# M068 register map
File version: 0.1
Registers are 32-bit, read-write, reset 0x0 unless marked. A register's access mark holds for its fields unless they carry their own. Offsets are from the block's base; [hi:lo] are bit positions; {n}, {i} and the like mark numbered series.

## UDFS2 — UDC2(USB -Spec2.0 Device contoller)
Base 0x40008200
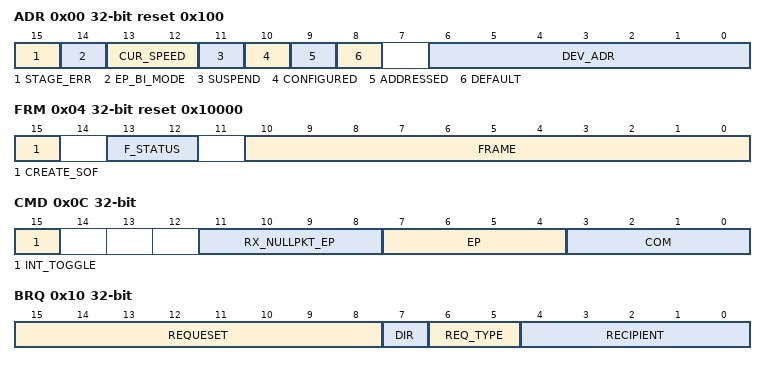
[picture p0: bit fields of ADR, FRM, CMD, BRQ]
0x00 ADR reset 0x100 — UDC2 Address State
  [15] STAGE_ERR, [14] EP_BI_MODE, [13:12] CUR_SPEED ro, [11] SUSPEND ro, [10] CONFIGURED, [9] ADDRESSED, [8] DEFAULT, [6:0] DEV_ADR
0x04 FRM reset 0x10000 — UDC2 Frame
  [15] CREATE_SOF, [13:12] F_STATUS ro, [10:0] FRAME ro
0x0C CMD — UDC2 Command
  [15] INT_TOGGLE, [11:8] RX_NULLPKT_EP ro, [7:4] EP, [3:0] COM
0x10 BRQ ro — UDC2 bRequest-bmRequest Type
  [15:8] REQUESET, [7] DIR, [6:5] REQ_TYPE, [4:0] RECIPIENT
0x14 WVL ro — UDC2 wValue
  [15:0] VALUE
0x18 WIDX ro — UDC2 wIndex
  [15:0] INDEX
0x1C WLGTH ro — UDC2 wLength
  [15:0] LENGTH
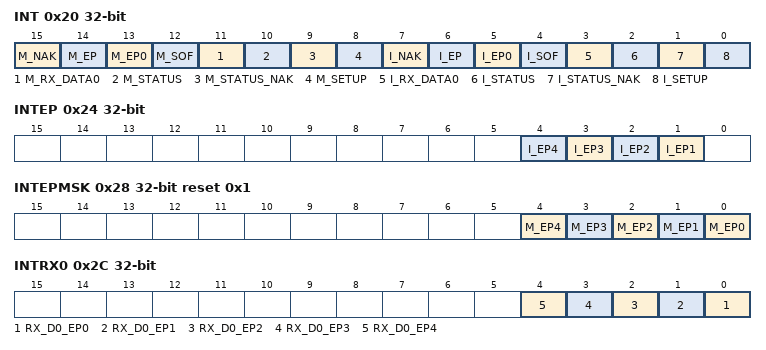
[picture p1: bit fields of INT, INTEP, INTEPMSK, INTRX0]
0x20 INT — UDC2 INT
  [15] M_NAK, [14] M_EP, [13] M_EP0, [12] M_SOF, [11] M_RX_DATA0, [10] M_STATUS, [9] M_STATUS_NAK, [8] M_SETUP, [7] I_NAK, [6] I_EP, [5] I_EP0, [4] I_SOF, [3] I_RX_DATA0, [2] I_STATUS, [1] I_STATUS_NAK, [0] I_SETUP
0x24 INTEP — UDC2 INT_EP
  [n] I_EP{n} (n=1..4)
0x28 INTEPMSK reset 0x1 — UDC2 INT_EP_MASK
  [n] M_EP{n} (n=0..4)
0x2C INTRX0 — UDC2 INT RX DATA0
  [n] RX_D0_EP{n} (n=0..4)
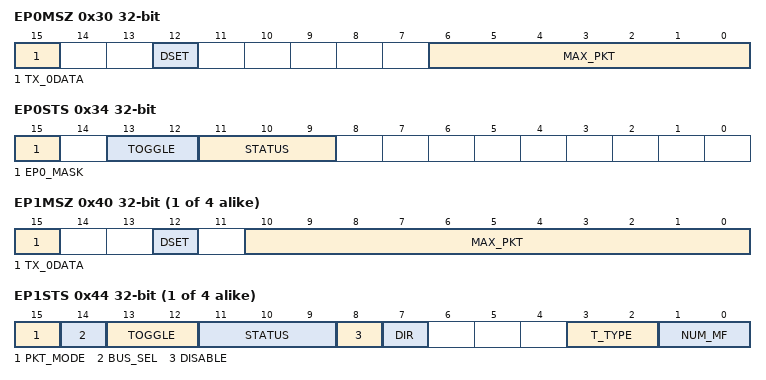
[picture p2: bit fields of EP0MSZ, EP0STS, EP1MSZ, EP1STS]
0x30 EP0MSZ — UDC2 EP0 Max Packet Size
  [15] TX_0DATA ro, [12] DSET ro, [6:0] MAX_PKT
0x34 EP0STS ro — UDC2 EP0 Status
  [15] EP0_MASK, [13:12] TOGGLE, [11:9] STATUS
0x38 EP0DSZ ro — UDC2 EP0 Data Size
  [6:0] SIZE
{0x3C+0x10*i} EP{i}FIFO (i=0..4) — UDC2 EP{i} FIFO
  [15:0] DATA
{0x30+0x10*i} EP{i}MSZ (i=1..4) — UDC2 EP{i} Max Packet Size
  [15] TX_0DATA ro, [12] DSET ro, [10:0] MAX_PKT
{0x34+0x10*i} EP{i}STS (i=1..4) — UDC2 EP{i} Status
  [15] PKT_MODE, [14] BUS_SEL, [13:12] TOGGLE ro, [11:9] STATUS ro, [8] DISABLE ro, [7] DIR, [3:2] T_TYPE, [1:0] NUM_MF
{0x38+0x10*i} EP{i}DSZ ro (i=1..4) — UDC2 EP{i} Data Size
  [10:0] SIZE
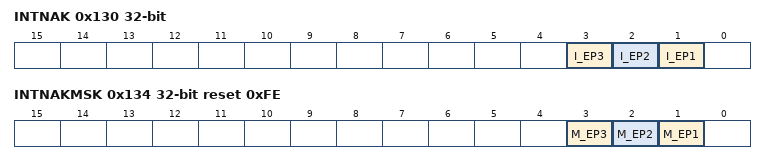
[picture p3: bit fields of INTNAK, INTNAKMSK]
0x130 INTNAK — UDC2 INT NAK
  [3] I_EP3, [2] I_EP2, [1] I_EP1
0x134 INTNAKMSK reset 0xFE — UDC2 INT NAK MASK
  [3] M_EP3, [2] M_EP2, [1] M_EP1

## INTIFAO — AO Area register1
Base 0x40038000
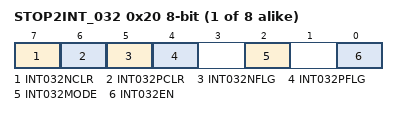
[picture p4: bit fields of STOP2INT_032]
{0x0+i} STOP2INT_{i:03} 8-bit (i=32..39) — STOP2INT I_F Control Register in AO Area
  [7] INT{i:03}NCLR, [6] INT{i:03}PCLR, [5] INT{i:03}NFLG, [4] INT{i:03}PFLG, [2] INT{i:03}MODE, [0] INT{i:03}EN

## AOREG — AO Area register2
Base 0x40038400
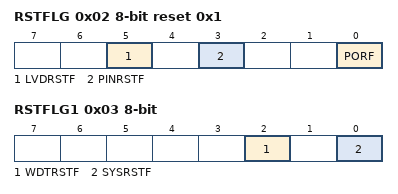
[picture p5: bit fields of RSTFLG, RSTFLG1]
0x02 RSTFLG 8-bit reset 0x1 — Reset Flag register
  [5] LVDRSTF, [3] PINRSTF, [0] PORF
0x03 RSTFLG1 8-bit — Reset Flag1 register
  [2] WDTRSTF, [0] SYSRSTF

## I2CS — I2C Wakeup I_F register
Base 0x40038800
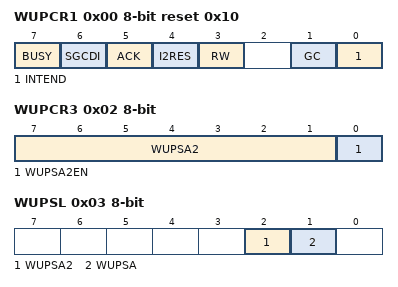
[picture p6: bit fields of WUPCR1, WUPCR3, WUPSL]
0x00 WUPCR1 8-bit reset 0x10 — I2C Wakeup control register1
  [7] BUSY ro, [6] SGCDI ro, [5] ACK, [4] I2RES, [3] RW ro, [1] GC, [0] INTEND
0x01 WUPCR2 8-bit — I2C Wakeup control register2
  [7:1] WUPSA1
0x02 WUPCR3 8-bit — I2C Wakeup control register3
  [7:1] WUPSA2, [0] WUPSA2EN
0x03 WUPSL 8-bit ro — I2C Wakeup Status register
  [2] WUPSA2, [1] WUPSA

## DMA — DMA Controller
Base 0x4004C000
0x00 STATUS ro reset 0x101F0000 — DMA Status Register
  [0] MASTER_ENABLE
0x04 CFG wo reset not defined — DMA Configuration Register
  [0] MASTER_ENABLE
0x08 CTRLBASEPTR — DMA Control Data Base Pointer Register
  [31:10] CTRL_BASE_PTR
0x0C ALTCTRLBASEPTR ro — DMA Channel Alternate Control Data Base Pointer Register
  [31:0] ALT_CTRL_BASE_PTR
0x14 CHNLSWREQUEST wo reset not defined — DMA Channel Software Request Register
  [31:0] CHNL_SW_REQUEST
0x18 CHNLUSEBURSTSET — DMA Channel Useburst Set Register
  [31:0] CHNL_USEBURST_SET
0x1C CHNLUSEBURSTCLR wo reset not defined — DMA Channel Useburst Clear Register
  [31:0] CHNL_USEBURST_CLR
0x20 CHNLREQMASKSET — DMA Channel Request Mask Set Register
  [31:0] CHNL_REQ_MASK_SET
0x24 CHNLREQMASKCLR wo reset not defined — DMA Channel Request Mask Clear Register
  [31:0] CHNL_REQ_MASK_CLR
0x28 CHNLENABLESET — DMA Channel Enable Set Register
  [31:0] CHNL_ENABLE_SET
0x2C CHNLENABLECLR wo reset not defined — DMA Channel Enable Clear Register
  [31:0] CHNL_ENABLE_CLR
0x30 CHNLPRIALTSET — DMA Channel Primary-Alternate Set Register
  [31:0] CHNL_PRI_ALT_SET
0x34 CHNLPRIALTCLR wo reset not defined — DMA Channel Primary-Alternate Clear Register
  [31:0] CHNL_PRI_ALT_CLR
0x38 CHNLPRIORITYSET — DMA Channel Priority Set Register
  [31:0] CHNL_PRIORITY_SET
0x3C CHNLPRIORITYCLR wo reset not defined — DMA Channel Priority Clear Register
  [31:0] CHNL_PRIORITY_CLR
0x4C ERRCLR — DMA Bus Error Clear Register
  [0] ERR_CLR
